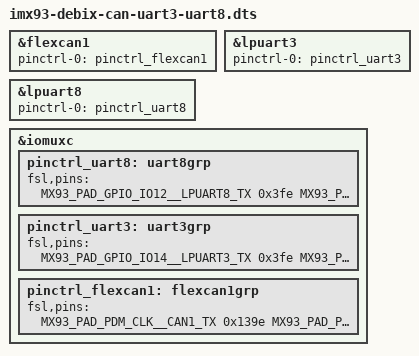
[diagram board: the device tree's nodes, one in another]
// SPDX-License-Identifier: (GPL-2.0+ OR MIT)
/*
 * Copyright 2022 NXP
 */

#include "imx93-11x11-evk.dts"

&flexcan1 {
        pinctrl-names = "default";
        pinctrl-0 = <&pinctrl_flexcan1>;
        status = "okay";
};

&lpuart3 {
	pinctrl-names = "default";
	pinctrl-0 = <&pinctrl_uart3>;
	status = "okay";
};

&lpuart8 {
	pinctrl-names = "default";
	pinctrl-0 = <&pinctrl_uart8>;
	status = "okay";
};



&iomuxc {
	pinctrl_uart8: uart8grp {
		fsl,pins = <
			MX93_PAD_GPIO_IO12__LPUART8_TX		0x3fe
			MX93_PAD_GPIO_IO13__LPUART8_RX		0x3fe
		>;
	};

	pinctrl_uart3: uart3grp {
		fsl,pins = <
			MX93_PAD_GPIO_IO14__LPUART3_TX		0x3fe
			MX93_PAD_GPIO_IO15__LPUART3_RX		0x3fe
		>;
	};

	pinctrl_flexcan1: flexcan1grp {
		fsl,pins = <
			MX93_PAD_PDM_CLK__CAN1_TX		0x139e
			MX93_PAD_PDM_BIT_STREAM0__CAN1_RX	0x139e
		>;
	};

};
